# PIC32CX2051BZ66048 register map
Vendor: Microchip Technology; Series: PIC32CXBZ66; File version: 0
CPU: CM4 r0p1, little endian, MPU, FPU, 3 interrupt priority bits, 58 interrupts
Registers are 32-bit, read-write, reset 0x0 unless marked. A register's access mark holds for its fields unless they carry their own. Offsets are from the block's base; [hi:lo] are bit positions; {n}, {i} and the like mark numbered series.

## CVD — Hardware CVD Controller Macro
Base 0x44002400
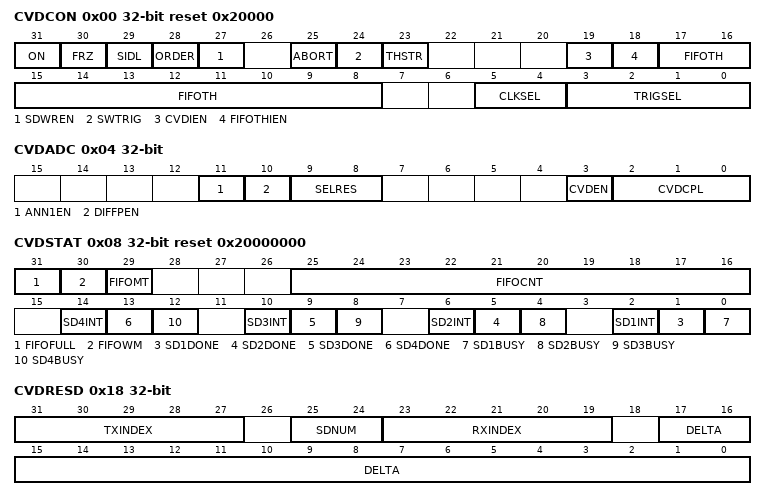
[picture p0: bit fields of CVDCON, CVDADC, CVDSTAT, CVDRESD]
0x00 CVDCON reset 0x20000 — CVD Control Register
  [31] ON — Enables the State Machine to scan enabled Scan Descriptors upon next trigger.
  [30] FRZ — Freeze Mode1= CVD controller halts in debugger mode0= CVD controller runs in debugger mode
  [29] SIDL — Stop in Idle Mode bit1= CVD controller halts when device enters Idle mode0= CVD controller continues running in Idle mode
  [28] ORDER — RX/TX Loop Order1= Scan all requested TX indexes, then increment RX index and continue0= Scan all requested RX indexes, then increment TX index and continue
  [27] SDWREN — Scan Descriptor Write Enable1= Enables writes to the scan descriptors, and prevents Scan Descriptor EN bits from being decoded and captured intoFSM_CLK domain by the Descriptor Selection Logic. This simplifies synchronization issues. The currently active ScanDescriptor registers should NOT be written even if SDWREN is asserted, as the FSM uses those bits directly without asynchronizer as a means of saving gates.0= Prevents writes to the scan descriptors, and enables the Descriptor Selector Logic to decode the next Scan Descriptor to run and capture it into the FSM domain.
  [25] ABORT — Instructs the controller to abort the current scan. The controller will move on to the next enabled ScanDescriptor if there is one, else it will go idle.Cleared by Hardware
  [24] SWTRIG — Software Trigger control. Starts scan manuallyCleared by Hardware.
  [23] THSTR — Threshold Store Mode1= Store only results which exceed the programmed threshold for the Scan Descriptor0= Store all results in FIFO
  [19] CVDIEN — Global Interrupt Enable for full macro. Gates any enabled FIFO or Scan Descriptor interrupts.
  [18] FIFOTHIEN — FIFO Threshold Interrupt Enable1= Controller will assert an interrupt when the FIFO threshold is met0= Controller will not assert an interrupt when the FIFO threshold is met
  [17:8] FIFOTH — Threshold for the results FIFO that will cause an interrupt and watermark FIFOWM status bitassertion
  [5:4] CLKSEL — Clock Select for FSM00= UPB_FSM_CLK01= External clock source 110= External clock source 211= External clock source 3
  [3:0] TRIGSEL — Selects one of 15 external trigger inputs to start scanning.
0x04 CVDADC — CVD ADC Configuration Register
  [11] ANN1EN — ANN1 channel enabled
  [10] DIFFPEN — Shared sarcore differential enabled
  [9:8] SELRES — Shared sarcore resolution select
  [3] CVDEN — Enable CVD
  [2:0] CVDCPL — Capacitor Party Line
0x08 CVDSTAT reset 0x20000000 — CVD Status Register
  [31] FIFOFULL — The Results FIFO is full.
  [30] FIFOWM — The Results FIFO has reached the programmed FIFOTHRESH threshold.
  [29] FIFOMT — The Results FIFO is empty.
  [25:16] FIFOCNT — Results FIFO word count: Indicates the number of words in the Results FIFO.
  [14] SD4INT — Scan Descriptor 4 has caused an interrupt.
  [4n-3] SD{n}DONE (n=1..4) — Core will set this bit if Scan Descriptor {n} has completed at least once. Core will clear this bit uponreceiving next trigger for Scan Descriptor {n}.
  [4n-4] SD{n}BUSY (n=1..4) — Scan Descriptor {n} is in progress
  [10] SD3INT — Scan Descriptor 3 has caused an interrupt
  [6] SD2INT — Scan Descriptor 2 has caused an interrupt
  [2] SD1INT — Scan Descriptor 1 has caused an interrupt
0x10 CVDRESH ro — CVD RESULTS POS FIFO Read Register (CVDRESH)
  [23:0] POS — The accumulated result of the positive-side measurements.Since the controller supports up to 128x oversampling, each polarity can accumulate up to 23 bits when using a 16-bitADC. The accumulation is not shifted back down to create an average. Therefore, if oversampling was requested, theSW will need to account for the left-shift of the result returned.
0x14 CVDRESL ro — CVD RESULTS NEG FIFO Read Register
  [23:0] NEG — The accumulated result of the negative-side measurements.Since the controller supports up to 128x oversampling, each polarity can accumulate up to 23 bits when using a 16-bitADC. The accumulation is not shifted back down to create an average. Therefore, if oversampling was requested, theSW will need to account for the left-shift of the result returned.
0x18 CVDRESD ro — CVD RESULTS DESCRIPTOR FIFO Read Register
  [31:27] TXINDEX — Transmit Index for this result. If the Stride of the Scan Descriptor was more than one, the Transmit Index indicates the first one of the group.
  [25:24] SDNUM — Scan Descriptor Number that generated this result
  [23:19] RXINDEX — Receive Index for this result. If the Stride of the Scan Descriptor was more than one, the ReceiveIndex indicates the first one of the group.
  [17:0] DELTA — Delta of the accumulated results of the negative-side and positive-side measurements.
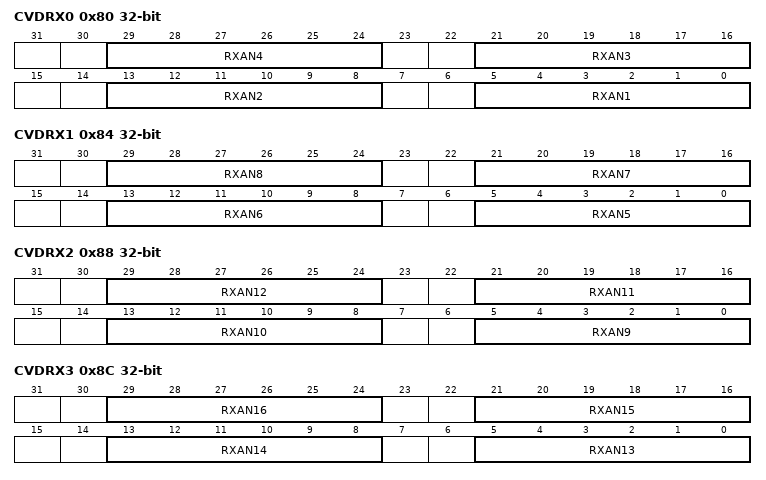
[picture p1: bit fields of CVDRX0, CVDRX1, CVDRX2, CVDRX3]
0x80 CVDRX0 — CVD RECEIVE INDEX 0-3 CONFIGURATION Register
  [8n-3:8n-8] RXAN{n} (n=1..4) — ANx/CVDR channel to use for RX Index {n-1}
0x84 CVDRX1 — CVD RECEIVE INDEX 4-7 CONFIGURATION Register
  [8n-35:8n-40] RXAN{n} (n=5..8) — ANx/CVDR channel to use for RX Index {n-1}
0x88 CVDRX2 — CVD RECEIVE INDEX 8-11 CONFIGURATION Register
  [8n-67:8n-72] RXAN{n} (n=9..12) — ANx/CVDR channel to use for RX Index {n-1}
0x8C CVDRX3 — CVD RECEIVE INDEX 12-15 CONFIGURATION Register
  [8n-99:8n-104] RXAN{n} (n=13..16) — ANx/CVDR channel to use for RX Index {n-1}
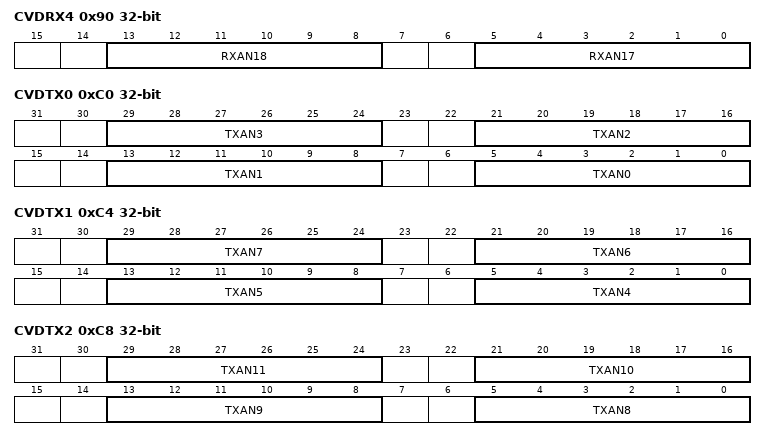
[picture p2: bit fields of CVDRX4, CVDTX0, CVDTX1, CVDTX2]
0x90 CVDRX4 — CVD RECEIVE INDEX 16-17 CONFIGURATION Register
  [13:8] RXAN18 — ANx/CVDR channel to use for RX Index 17
  [5:0] RXAN17 — ANx/CVDR channel to use for RX Index 16
0xC0 CVDTX0 — CVD TRANSMIT INDEX 0-3 NCONFIGURATION
  [8n+5:8n] TXAN{n} (n=0..3) — CVDT channel to use for TX Index {n}
0xC4 CVDTX1 — CVD TRANSMIT INDEX 4-7 NCONFIGURATION
  [8n-27:8n-32] TXAN{n} (n=4..7) — CVDT channel to use for TX Index {n}
0xC8 CVDTX2 — CVD TRANSMIT INDEX 8-11 NCONFIGURATION
  [8n-59:8n-64] TXAN{n} (n=8..11) — CVDT channel to use for TX Index {n}
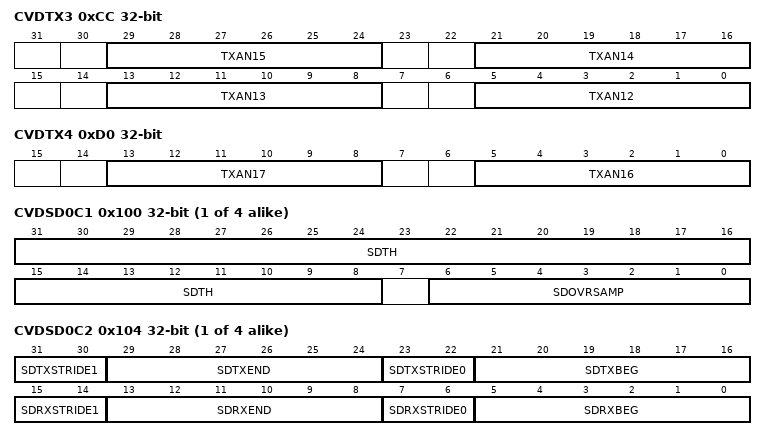
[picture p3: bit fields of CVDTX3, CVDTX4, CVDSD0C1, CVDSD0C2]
0xCC CVDTX3 — CVD TRANSMIT INDEX 12-15 NCONFIGURATION
  [8n-91:8n-96] TXAN{n} (n=12..15) — CVDT channel to use for TX Index {n}
0xD0 CVDTX4 — CVD TRANSMIT INDEX 12-15 NCONFIGURATION
  [13:8] TXAN17 — CVDT channel to use for TX Index 17
  [5:0] TXAN16 — CVDT channel to use for TX Index 16
{0x100+0x10*i} CVDSD{i}C1 (i=0..3) — CVD SCAN DESCRIPTOR N CONTROL1 REGISTER
  [31:8] SDTH — Scan Descriptor Threshold.
  [6:0] SDOVRSAMP — Scan Descriptor Over Sampling0= One measurement1= Two measurements accumulated...127= 128 measurements accumulated
{0x104+0x10*i} CVDSD{i}C2 (i=0..3) — CVD SCAN DESCRIPTOR N CONTROL2 REGISTER
  [31:30] SDTXSTRIDE1 — Scan Descriptor TX Index StrideDetermines the number of TX Indexes included in a single measurement.4'h0= One TX Index4'bF= 16TX Indexes
  [29:24] SDTXEND — Scan Descriptor TX Index EndDetermines the last TX index to include in a scan.One the TX index pointer, which is incremented by the SDnTXSTRIDE+1 value, meets or exceeds this value, the TXloop of the scan is complete.
  [23:22] SDTXSTRIDE0 — Scan Descriptor TX Index StrideDetermines the number of TX Indexes included in a single measurement.4'h0= One TX Index4'bF= 16TX Indexes
  [21:16] SDTXBEG — Scan Descriptor TX Index StartDetermines the first TX index to include in a scan.
  [15:14] SDRXSTRIDE1 — Scan Descriptor RX Index StrideDetermines the number of RX Indexes included in a single measurement4'h0= One RX Index4'hF= 16 TX Indexes
  [13:8] SDRXEND — Scan Descriptor RX Index EndDetermines the last RX index to include in a scan.One the RX index pointer, which is incremented by the SDnRXSTRIDE+1 value, meets or exceeds this value, the RXloop of the scan is complete.
  [7:6] SDRXSTRIDE0 — Scan Descriptor RX Index StrideDetermines the number of RX Indexes included in a single measurement4'h0= One RX Index4'hF= 16 TX Indexes
  [5:0] SDRXBEG — Scan Descriptor RX Index StartDetermines the first RX index to include in a scan.
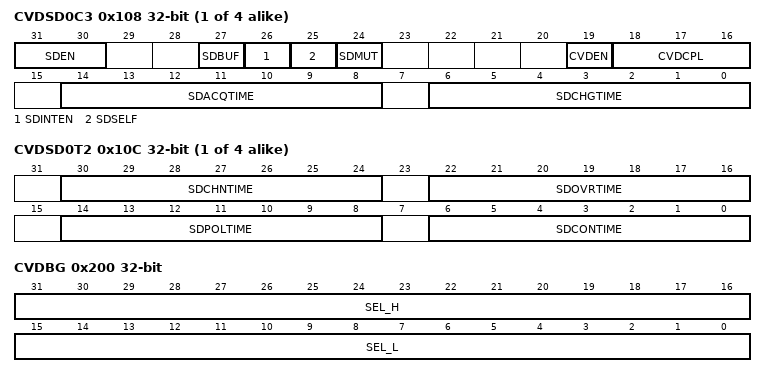
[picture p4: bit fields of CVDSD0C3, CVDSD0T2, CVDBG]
{0x108+0x10*i} CVDSD{i}C3 (i=0..3) — CVD SCAN DESCRIPTOR N CONTROL3 REGISTER
  [31:30] SDEN — Scan Descriptor Enable Mode00= Scan Descriptor Disabled01= Execute Scan Descriptor one time only, then clear the enable.10= Execute the Scan Descriptor, but keep enabled. Move on to next enabled descriptors.11= Execute the Scan Descriptor in a loop until a threshold match is detected, then clear the enable and move on tonext enabled descriptors.
  [27] SDBUF — Scan Descriptor CVD Buffer Enable1= Use the SOC's CVD Buffer macro to drive the party-line (shared ADC core input) rather than the RX outputs0= SOC's CVD Buffer macro not used to drive party-line (or doesn't exist)
  [26] SDINTEN — Scan Descriptor Interrupt Enable1= Scan Descriptor creates an interrupt if the accumulator threshold is met0= Scan descriptor does not create an interrupt
  [25] SDSELF — Scan Descriptor Mutual Mode1= Self Measurement Mode; RX outputs are part of CVD measurement and are driven0= No Self Measurement; RX outputs are not part of CVD measurements
  [24] SDMUT — Scan Descriptor Mutual Mode1= Mutual Measurement Mode; TX outputs are part of CVD measurement and are driven0=No Mutual Measurement Mode; TX outputs are not part of CVD measurements
  [19] CVDEN — Capacitive Voltage Division Enable bit
  [18:16] CVDCPL — Capacitor Voltage Divider (CVD) Setting bits
  [14:8] SDACQTIME — Scan Descriptor Acquire TimeControls the number of cycles (clock based on CVDCON.CLKSEL[1:0]) the state machine waits in the ACQUIRE stateto allow the ADC voltage to settle
  [6:0] SDCHGTIME — Scan Descriptor Charge TimeControls the number of cycles (clock based on CVDCON.CLKSEL[1:0]) the state machine waits in the CHARGE statedriving both the internal and external capacitor nodes, as well as the TX output(s)
{0x10C+0x10*i} CVDSD{i}T2 (i=0..3) — CVD SCAN DESCRIPTOR N TIME2 REGISTER
  [30:24] SDCHNTIME — Scan Descriptor Channel TimeControls the number of cycles (clock based on CVDCON.CLKSEL[1:0]) the state machine waits in the RXCHAN orTXCHAN state before moving to the next RX/TX pair
  [22:16] SDOVRTIME — Scan Descriptor Oversample TimeControls the number of cycles (clock based on CVDCON.CLKSEL[1:0]) the state machine waits in the OVERSAMPstate before taking the next oversampling measurement of an RX/TX pair.
  [14:8] SDPOLTIME — Scan Descriptor Polarity TimeControls the number of cycles (clock based on CVDCON.CLKSEL[1:0]) the state machine waits in the POLARITY statebefore taking the second polarity measurement of an RX/TX pair
  [6:0] SDCONTIME — Scan Descriptor Charge TimeControls the number of cycles (clock based on CVDCON.CLKSEL[1:0]) the state machine waits in the CONVERT statewaiting for the ADC sample data. It must be ensured that the ADC will assert End-Of-Convert (EOC) before the CONVERT state timer expires.
0x200 CVDBG — CVD DEBUG REGISTER
  [31:16] SEL_H — Select signal to MUX debug signals on to port cvd_tst_dbg_data[31:16]
  [15:0] SEL_L — Select signal to MUX debug signals on to port cvd_tst_dbg_data[15:0]
